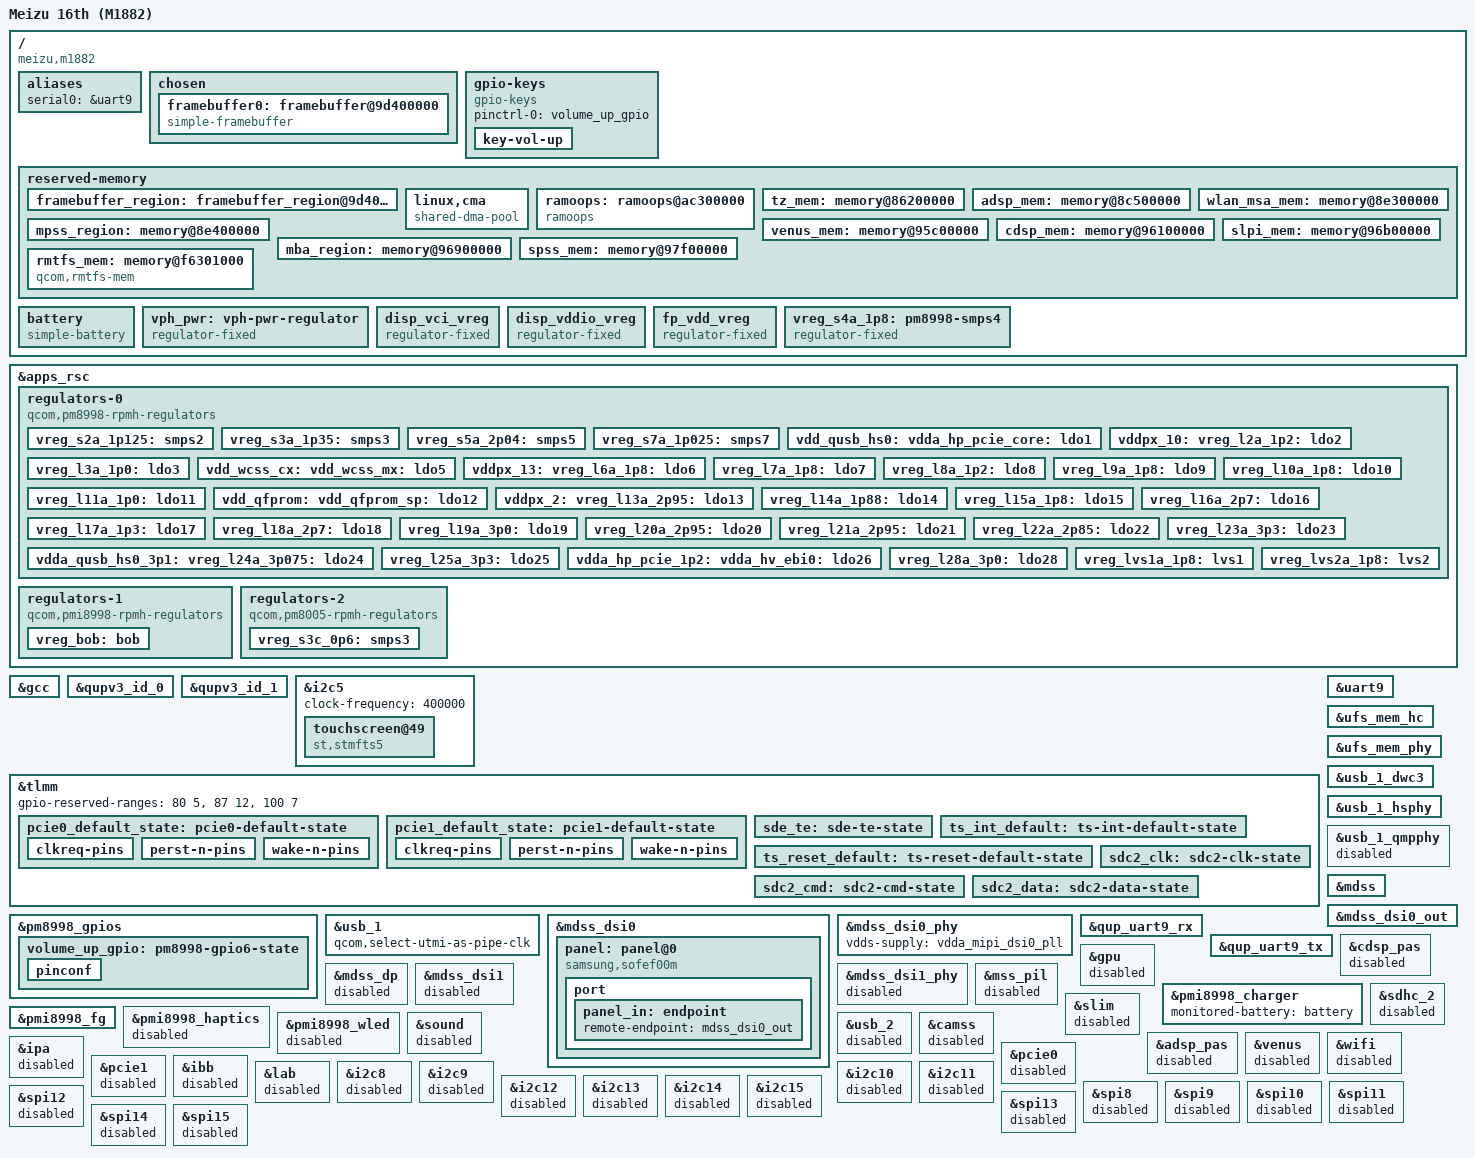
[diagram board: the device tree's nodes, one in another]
// SPDX-License-Identifier: GPL-2.0
/*
 * SDM845 Meizu 16th (M1882) device tree
 *
 * Copyright (c) 2026, The Linux Foundation. All rights reserved.
 */

/dts-v1/;

#include <dt-bindings/gpio/gpio.h>
#include <dt-bindings/input/linux-event-codes.h>
#include <dt-bindings/interrupt-controller/irq.h>
#include <dt-bindings/pinctrl/qcom,pmic-gpio.h>
#include <dt-bindings/regulator/qcom,rpmh-regulator.h>
#include <dt-bindings/arm/qcom,ids.h>
#include <dt-bindings/clock/qcom,gcc-sdm845.h>
#include "sdm845.dtsi"
#include "pm8998.dtsi"
#include "pmi8998.dtsi"

/delete-node/ &tz_mem;
/delete-node/ &adsp_mem;
/delete-node/ &wlan_msa_mem;
/delete-node/ &mpss_region;
/delete-node/ &venus_mem;
/delete-node/ &cdsp_mem;
/delete-node/ &mba_region;
/delete-node/ &slpi_mem;
/delete-node/ &spss_mem;
/delete-node/ &rmtfs_mem;

/ {
	model = "Meizu 16th (M1882)";
	compatible = "meizu,m1882", "qcom,sdm845";
	chassis-type = "handset";

	qcom,msm-id = <0x141 0x20001>;
	qcom,board-id = <0x08 0x00>;

	aliases {
		serial0 = &uart9;
	};

	chosen {
		#address-cells = <2>;
		#size-cells = <2>;
		ranges;

		stdout-path = "serial0:115200n8";

		bootargs = "console=tty0 earlycon keep_bootcon ignore_loglevel no_console_suspend";

		framebuffer0: framebuffer@9d400000 {
			compatible = "simple-framebuffer";
			memory-region = <&framebuffer_region>;

			format = "a8r8g8b8";
			width = <1080>;
			height = <2160>;
			stride = <(1080 * 4)>;
		};
	};

	gpio-keys {
		compatible = "gpio-keys";

		pinctrl-names = "default";
		pinctrl-0 = <&volume_up_gpio>;

		key-vol-up {
			label = "Volume up";
			linux,code = <KEY_VOLUMEUP>;
			gpios = <&pm8998_gpios 6 GPIO_ACTIVE_LOW>;
		};
	};

	reserved-memory {
		#address-cells = <2>;
		#size-cells = <2>;
		ranges;

		framebuffer_region: framebuffer_region@9d400000 {
			reg = <0x0 0x9d400000 0x0 0x02400000>;
			no-map;
		};

		linux,cma {
			compatible = "shared-dma-pool";
			alloc-ranges = <0 0x00000000 0 0xffffffff>;
			reusable;
			alignment = <0 0x400000>;
			size = <0 0x2c00000>;
			linux,cma-default;
		};

		ramoops: ramoops@ac300000 {
			compatible = "ramoops";
			reg = <0 0xac300000 0 0x400000>;
			record-size = <0x40000>;
			console-size = <0x40000>;
			ftrace-size = <0x40000>;
			pmsg-size = <0x200000>;
		};

		tz_mem: memory@86200000 {
			reg = <0 0x86200000 0 0x4900000>;
			no-map;
		};

		adsp_mem: memory@8c500000 {
			reg = <0 0x8c500000 0 0x1e00000>;
			no-map;
		};

		wlan_msa_mem: memory@8e300000 {
			reg = <0 0x8e300000 0 0x100000>;
			no-map;
		};

		mpss_region: memory@8e400000 {
			reg = <0 0x8e400000 0 0x7800000>;
			no-map;
		};

		venus_mem: memory@95c00000 {
			reg = <0 0x95c00000 0 0x500000>;
			no-map;
		};

		cdsp_mem: memory@96100000 {
			reg = <0 0x96100000 0 0x800000>;
			no-map;
		};

		mba_region: memory@96900000 {
			reg = <0 0x96900000 0 0x200000>;
			no-map;
		};

		slpi_mem: memory@96b00000 {
			reg = <0 0x96b00000 0 0x1400000>;
			no-map;
		};

		spss_mem: memory@97f00000 {
			reg = <0 0x97f00000 0 0x100000>;
			no-map;
		};

		rmtfs_mem: memory@f6301000 {
			compatible = "qcom,rmtfs-mem";
			reg = <0 0xf6301000 0 0x200000>;
			no-map;

			qcom,client-id = <1>;
			qcom,vmid = <QCOM_SCM_VMID_MSS_MSA>;
		};
	};

		battery: battery {
		compatible = "simple-battery";

		charge-full-design-microamp-hours = <3010000>;
		voltage-min-design-microvolt = <3300000>;
		voltage-max-design-microvolt = <4400000>;
		constant-charge-current-max-microamp = <2950000>;
	};

	vph_pwr: vph-pwr-regulator {
		compatible = "regulator-fixed";
		regulator-name = "vph_pwr";
		regulator-min-microvolt = <3700000>;
		regulator-max-microvolt = <3700000>;
	};

	disp_vci_vreg: disp_vci_vreg {
		compatible = "regulator-fixed";
		regulator-name = "disp_vci_vreg";
		start-delay-us = <4000>;
		regulator-always-on;
		regulator-boot-on;
		enable-active-high;
		gpio = <&tlmm 99 0>;
	};

	disp_vddio_vreg: disp_vddio_vreg {
		compatible = "regulator-fixed";
		regulator-name = "disp_vddio_vreg";
		startup-delay-us = <4000>;
		regulator-always-on;
		regulator-boot-on;
		enable-active-high;
		gpio = <&tlmm 79 0>;
	};

	fp_vdd_vreg: fp_vdd_vreg {
		compatible = "regulator-fixed";
		regulator-name = "fp_vdd_vreg";
		startup-delay-us = <4000>;
		regulator-always-on;
		enable-active-high;
		gpio = <&tlmm 50 0>;
	};

	vreg_s4a_1p8: pm8998-smps4 {
		compatible = "regulator-fixed";
		regulator-name = "vreg_s4a_1p8";

		regulator-min-microvolt = <1800000>;
		regulator-max-microvolt = <1800000>;

		regulator-always-on;
		regulator-boot-on;

		vin-supply = <&vph_pwr>;
	};
};

&apps_rsc {
	regulators-0 {
		compatible = "qcom,pm8998-rpmh-regulators";
		qcom,pmic-id = "a";

		vdd-s1-supply = <&vph_pwr>;
		vdd-s2-supply = <&vph_pwr>;
		vdd-s3-supply = <&vph_pwr>;
		vdd-s4-supply = <&vph_pwr>;
		vdd-s5-supply = <&vph_pwr>;
		vdd-s6-supply = <&vph_pwr>;
		vdd-s7-supply = <&vph_pwr>;
		vdd-s8-supply = <&vph_pwr>;
		vdd-s9-supply = <&vph_pwr>;
		vdd-s10-supply = <&vph_pwr>;
		vdd-s11-supply = <&vph_pwr>;
		vdd-s12-supply = <&vph_pwr>;
		vdd-s13-supply = <&vph_pwr>;
		vdd-l1-l27-supply = <&vreg_s7a_1p025>;
		vdd-l2-l8-l17-supply = <&vreg_s3a_1p35>;
		vdd-l3-l11-supply = <&vreg_s7a_1p025>;
		vdd-l4-l5-supply = <&vreg_s7a_1p025>;
		vdd-l6-supply = <&vph_pwr>;
		vdd-l7-l12-l14-l15-supply = <&vreg_s5a_2p04>;
		vdd-l9-supply = <&vreg_bob>;
		vdd-l10-l23-l25-supply = <&vreg_bob>;
		vdd-l13-l19-l21-supply = <&vreg_bob>;
		vdd-l16-l28-supply = <&vreg_bob>;
		vdd-l18-l22-supply = <&vreg_bob>;
		vdd-l20-l24-supply = <&vreg_bob>;
		vdd-l26-supply = <&vreg_s3a_1p35>;
		vin-lvs-1-2-supply = <&vreg_s4a_1p8>;

		vreg_s2a_1p125: smps2 {
			regulator-min-microvolt = <1100000>;
			regulator-max-microvolt = <1100000>;
		};

		vreg_s3a_1p35: smps3 {
			regulator-min-microvolt = <1352000>;
			regulator-max-microvolt = <1352000>;
		};

		vreg_s5a_2p04: smps5 {
			regulator-min-microvolt = <1904000>;
			regulator-max-microvolt = <2040000>;
		};

		vreg_s7a_1p025: smps7 {
			regulator-min-microvolt = <900000>;
			regulator-max-microvolt = <1028000>;
		};

		vdd_qusb_hs0:
		vdda_hp_pcie_core:
		vdda_mipi_csi0_0p9:
		vdda_mipi_csi1_0p9:
		vdda_mipi_csi2_0p9:
		vdda_mipi_dsi0_pll:
		vdda_mipi_dsi1_pll:
		vdda_qlink_lv:
		vdda_qlink_lv_ck:
		vdda_qrefs_0p875:
		vdda_pcie_core:
		vdda_pll_cc_ebi01:
		vdda_pll_cc_ebi23:
		vdda_sp_sensor:
		vdda_ufs1_core:
		vdda_ufs2_core:
		vdda_usb1_ss_core:
		vdda_usb2_ss_core:
		vreg_l1a_0p875: ldo1 {
			regulator-min-microvolt = <880000>;
			regulator-max-microvolt = <880000>;
			regulator-initial-mode = <RPMH_REGULATOR_MODE_HPM>;
		};

		vddpx_10:
		vreg_l2a_1p2: ldo2 {
			regulator-min-microvolt = <1200000>;
			regulator-max-microvolt = <1200000>;
			regulator-initial-mode = <RPMH_REGULATOR_MODE_HPM>;
			regulator-always-on;
		};

		vreg_l3a_1p0: ldo3 {
			regulator-min-microvolt = <1000000>;
			regulator-max-microvolt = <1000000>;
			regulator-initial-mode = <RPMH_REGULATOR_MODE_HPM>;
		};

		vdd_wcss_cx:
		vdd_wcss_mx:
		vdda_wcss_pll:
		vreg_l5a_0p8: ldo5 {
			regulator-min-microvolt = <800000>;
			regulator-max-microvolt = <800000>;
			regulator-initial-mode = <RPMH_REGULATOR_MODE_HPM>;
		};

		vddpx_13:
		vreg_l6a_1p8: ldo6 {
			regulator-min-microvolt = <1856000>;
			regulator-max-microvolt = <1856000>;
			regulator-initial-mode = <RPMH_REGULATOR_MODE_HPM>;
		};

		vreg_l7a_1p8: ldo7 {
			regulator-min-microvolt = <1800000>;
			regulator-max-microvolt = <1800000>;
			regulator-initial-mode = <RPMH_REGULATOR_MODE_HPM>;
		};

		vreg_l8a_1p2: ldo8 {
			regulator-min-microvolt = <1200000>;
			regulator-max-microvolt = <1248000>;
			regulator-initial-mode = <RPMH_REGULATOR_MODE_HPM>;
		};

		vreg_l9a_1p8: ldo9 {
			regulator-min-microvolt = <1704000>;
			regulator-max-microvolt = <2928000>;
			regulator-initial-mode = <RPMH_REGULATOR_MODE_HPM>;
		};

		vreg_l10a_1p8: ldo10 {
			regulator-min-microvolt = <1704000>;
			regulator-max-microvolt = <2928000>;
			regulator-initial-mode = <RPMH_REGULATOR_MODE_HPM>;
		};

		vreg_l11a_1p0: ldo11 {
			regulator-min-microvolt = <1000000>;
			regulator-max-microvolt = <1048000>;
			regulator-initial-mode = <RPMH_REGULATOR_MODE_HPM>;
		};

		vdd_qfprom:
		vdd_qfprom_sp:
		vdda_apc1_cs_1p8:
		vdda_gfx_cs_1p8:
		vdda_qrefs_1p8:
		vdda_qusb_hs0_1p8:
		vddpx_11:
		vreg_l12a_1p8: ldo12 {
			regulator-min-microvolt = <1800000>;
			regulator-max-microvolt = <1800000>;
			regulator-initial-mode = <RPMH_REGULATOR_MODE_HPM>;
		};

		vddpx_2:
		vreg_l13a_2p95: ldo13 {
			regulator-min-microvolt = <1800000>;
			regulator-max-microvolt = <2960000>;
			regulator-initial-mode = <RPMH_REGULATOR_MODE_HPM>;
		};

		vreg_l14a_1p88: ldo14 {
			regulator-min-microvolt = <1800000>;
			regulator-max-microvolt = <1800000>;
			regulator-initial-mode = <RPMH_REGULATOR_MODE_HPM>;
		};

		vreg_l15a_1p8: ldo15 {
			regulator-min-microvolt = <1800000>;
			regulator-max-microvolt = <1800000>;
			regulator-initial-mode = <RPMH_REGULATOR_MODE_HPM>;
		};

		vreg_l16a_2p7: ldo16 {
			regulator-min-microvolt = <2704000>;
			regulator-max-microvolt = <2704000>;
			regulator-initial-mode = <RPMH_REGULATOR_MODE_HPM>;
		};

		vreg_l17a_1p3: ldo17 {
			regulator-min-microvolt = <1304000>;
			regulator-max-microvolt = <1304000>;
			regulator-initial-mode = <RPMH_REGULATOR_MODE_HPM>;
		};

		vreg_l18a_2p7: ldo18 {
			regulator-min-microvolt = <2704000>;
			regulator-max-microvolt = <2960000>;
			regulator-initial-mode = <RPMH_REGULATOR_MODE_HPM>;
		};

		vreg_l19a_3p0: ldo19 {
			regulator-min-microvolt = <2856000>;
			regulator-max-microvolt = <3104000>;
			regulator-initial-mode = <RPMH_REGULATOR_MODE_HPM>;
		};

		vreg_l20a_2p95: ldo20 {
			regulator-min-microvolt = <2704000>;
			regulator-max-microvolt = <2960000>;
			regulator-initial-mode = <RPMH_REGULATOR_MODE_HPM>;
		};

		vreg_l21a_2p95: ldo21 {
			regulator-min-microvolt = <2704000>;
			regulator-max-microvolt = <2960000>;
			regulator-initial-mode = <RPMH_REGULATOR_MODE_HPM>;
		};

		vreg_l22a_2p85: ldo22 {
			regulator-min-microvolt = <2864000>;
			regulator-max-microvolt = <3312000>;
			regulator-initial-mode = <RPMH_REGULATOR_MODE_HPM>;
		};

		vreg_l23a_3p3: ldo23 {
			regulator-min-microvolt = <3000000>;
			regulator-max-microvolt = <3312000>;
			regulator-initial-mode = <RPMH_REGULATOR_MODE_HPM>;
		};

		vdda_qusb_hs0_3p1:
		vreg_l24a_3p075: ldo24 {
			regulator-min-microvolt = <3088000>;
			regulator-max-microvolt = <3088000>;
			regulator-initial-mode = <RPMH_REGULATOR_MODE_HPM>;
		};

		vreg_l25a_3p3: ldo25 {
			regulator-min-microvolt = <3300000>;
			regulator-max-microvolt = <3312000>;
			regulator-initial-mode = <RPMH_REGULATOR_MODE_HPM>;
		};

		vdda_hp_pcie_1p2:
		vdda_hv_ebi0:
		vdda_hv_ebi1:
		vdda_hv_ebi2:
		vdda_hv_ebi3:
		vdda_mipi_csi_1p25:
		vdda_mipi_dsi0_1p2:
		vdda_mipi_dsi1_1p2:
		vdda_pcie_1p2:
		vdda_ufs1_1p2:
		vdda_ufs2_1p2:
		vdda_usb1_ss_1p2:
		vdda_usb2_ss_1p2:
		vreg_l26a_1p2: ldo26 {
			regulator-min-microvolt = <1200000>;
			regulator-max-microvolt = <1200000>;
			regulator-initial-mode = <RPMH_REGULATOR_MODE_HPM>;
		};

		vreg_l28a_3p0: ldo28 {
			regulator-min-microvolt = <2856000>;
			regulator-max-microvolt = <3008000>;
			regulator-initial-mode = <RPMH_REGULATOR_MODE_HPM>;
		};

		vreg_lvs1a_1p8: lvs1 {
			regulator-min-microvolt = <1800000>;
			regulator-max-microvolt = <1800000>;
		};

		vreg_lvs2a_1p8: lvs2 {
			regulator-min-microvolt = <1800000>;
			regulator-max-microvolt = <1800000>;
		};
	};

	regulators-1 {
		compatible = "qcom,pmi8998-rpmh-regulators";
		qcom,pmic-id = "b";

		vdd-bob-supply = <&vph_pwr>;

		vreg_bob: bob {
			regulator-min-microvolt = <3312000>;
			regulator-max-microvolt = <3600000>;
			regulator-initial-mode = <RPMH_REGULATOR_MODE_AUTO>;
			regulator-allow-bypass;
		};
	};

	regulators-2 {
		compatible = "qcom,pm8005-rpmh-regulators";
		qcom,pmic-id = "c";

		vdd-s1-supply = <&vph_pwr>;
		vdd-s2-supply = <&vph_pwr>;
		vdd-s3-supply = <&vph_pwr>;
		vdd-s4-supply = <&vph_pwr>;

		vreg_s3c_0p6: smps3 {
			regulator-min-microvolt = <600000>;
			regulator-max-microvolt = <600000>;
		};
	};
};

&gcc {
	protected-clocks = <GCC_QSPI_CORE_CLK>,
			   <GCC_QSPI_CORE_CLK_SRC>,
			   <GCC_QSPI_CNOC_PERIPH_AHB_CLK>,
			   <GCC_LPASS_Q6_AXI_CLK>,
			   <GCC_LPASS_SWAY_CLK>,
			   <GCC_CPUSS_AHB_CLK>,
			   <GCC_CPUSS_AHB_CLK_SRC>,
			   <GCC_CPUSS_RBCPR_CLK>,
			   <GCC_CPUSS_RBCPR_CLK_SRC>,
			   <GCC_SYS_NOC_CPUSS_AHB_CLK>,
			   <GCC_CPUSS_DVM_BUS_CLK>,
			   <GCC_CPUSS_GNOC_CLK>;
};

&qupv3_id_0 {
	status = "okay";
};

&qupv3_id_1 {
	status = "okay";
};

&i2c5 {
	clock-frequency = <400000>;

	status = "okay";

	touchscreen@49 {
		compatible = "st,stmfts5";
		reg = <0x49>;

		interrupts-extended = <&tlmm 125 IRQ_TYPE_LEVEL_LOW>;

		reset-gpios = <&tlmm 126 GPIO_ACTIVE_LOW>;

		pinctrl-names = "default";
		pinctrl-0 = <&ts_int_default &ts_reset_default>;

		avdd-supply = <&vreg_l28a_3p0>;
		vdd-supply = <&vreg_l14a_1p88>;

		touchscreen-size-x = <1080>;
		touchscreen-size-y = <2160>;
	};
};

&tlmm {
	pcie0_default_state: pcie0-default-state {
		clkreq-pins {
			pins = "gpio36";
			function = "pci_e0";
			bias-pull-up;
		};

		perst-n-pins {
			pins = "gpio35";
			function = "gpio";
			drive-strength = <2>;
			bias-pull-down;
		};

		wake-n-pins {
			pins = "gpio37";
			function = "gpio";
			drive-strength = <2>;
			bias-pull-up;
		};
	};

	pcie1_default_state: pcie1-default-state {
		clkreq-pins {
			pins = "gpio103";
			function = "pci_e1";
			bias-pull-up;
		};

		perst-n-pins {
			pins = "gpio102";
			function = "gpio";
			drive-strength = <16>;
			bias-pull-down;
		};

		wake-n-pins {
			pins = "gpio104";
			function = "gpio";
			drive-strength = <2>;
			bias-pull-up;
		};
	};
};

&pm8998_gpios {
	volume_up_gpio: pm8998-gpio6-state {
		pinconf {
			pins = "gpio6";
			function = "normal";
			input-enable;
			bias-pull-up;
			qcom,drive-strength = <PMIC_GPIO_STRENGTH_NO>;
		};
	};
};

&uart9 {
	status = "okay";
};

&ufs_mem_hc {
	status = "okay";

	reset-gpios = <&tlmm 150 GPIO_ACTIVE_LOW>;

	vcc-supply = <&vreg_l20a_2p95>;
	vcc-max-microamp = <600000>;
};

&ufs_mem_phy {
	status = "okay";

	vdda-phy-supply = <&vdda_ufs1_core>;
	vdda-pll-supply = <&vdda_ufs1_1p2>;
};

&usb_1 {
	qcom,select-utmi-as-pipe-clk;

	status = "okay";
};

&usb_1_dwc3 {
	dr_mode = "peripheral";

	maximum-speed = "high-speed";

	phys = <&usb_1_hsphy>;
	phy-names = "usb2-phy";
};

&usb_1_hsphy {
	status = "okay";

	vdd-supply = <&vdda_usb1_ss_core>;
	vdda-pll-supply = <&vdda_qusb_hs0_1p8>;
	vdda-phy-dpdm-supply = <&vdda_qusb_hs0_3p1>;

	post-init-providers = <&vreg_l1a_0p875
			       &vreg_l12a_1p8
			       &vreg_l24a_3p075>;

	qcom,imp-res-offset-value = <8>;
	qcom,hstx-trim-value = <QUSB2_V2_HSTX_TRIM_21_6_MA>;
	qcom,preemphasis-level = <QUSB2_V2_PREEMPHASIS_5_PERCENT>;
	qcom,preemphasis-width = <QUSB2_V2_PREEMPHASIS_WIDTH_HALF_BIT>;
};

&usb_1_qmpphy {
	status = "disabled";
};

&mdss {
	status = "okay";
};

&mdss_dsi0 {
	status = "okay";
	vdda-supply = <&vdda_mipi_dsi0_1p2>;

	pinctrl-names = "default", "sleep";
	pinctrl-0 = <&sde_te>;
	pinctrl-1 = <&sde_te>;

	panel: panel@0 {
		compatible = "samsung,sofef00m";
		reg = <0>;

		vddio-supply = <&disp_vddio_vreg>;
		vdd-supply = <&disp_vci_vreg>;

		reset-gpios = <&pm8998_gpios 8 GPIO_ACTIVE_LOW>;

		port {
			panel_in: endpoint {
				remote-endpoint = <&mdss_dsi0_out>;
			};
		};
	};
};

&mdss_dsi0_out {
	remote-endpoint = <&panel_in>;
	data-lanes = <0 1 2 3>;
};

&mdss_dsi0_phy {
	status = "okay";
	vdds-supply = <&vdda_mipi_dsi0_pll>;
};

&qup_uart9_rx {
	drive-strength = <2>;
	bias-pull-up;
};

&qup_uart9_tx {
	drive-strength = <2>;
	bias-disable;
};

&tlmm {
	gpio-reserved-ranges = <80 5>, <87 12>, <100 7>;

	sde_te: sde-te-state {
		pins = "gpio10";
		function = "mdp_vsync";
		drive-strength = <2>;
		bias-pull-down;
	};

	ts_int_default: ts-int-default-state {
		pins = "gpio125";
		function = "gpio";
		drive-strength = <2>;
		bias-pull-up;
	};

	ts_reset_default: ts-reset-default-state {
		pins = "gpio126";
		function = "gpio";
		drive-strength = <2>;
		bias-disable;
	};

	sdc2_clk: sdc2-clk-state {
		pins = "sdc2_clk";
		bias-disable;
		drive-strength = <16>;
	};

	sdc2_cmd: sdc2-cmd-state {
		pins = "sdc2_cmd";
		bias-pull-up;
		drive-strength = <16>;
	};

	sdc2_data: sdc2-data-state {
		pins = "sdc2_data";
		bias-pull-up;
		drive-strength = <16>;
	};
};

&cdsp_pas { status = "disabled"; };
&gpu { status = "disabled"; };
&mdss_dp { status = "disabled"; };
&mdss_dsi1 { status = "disabled"; };
&mdss_dsi1_phy { status = "disabled"; };
&mss_pil { status = "disabled"; };
&pmi8998_charger {
	monitored-battery = <&battery>;

	status = "okay";
};

&pmi8998_fg {
	monitored-battery = <&battery>;
	power-supplies = <&pmi8998_charger>;

	status = "okay";
};

&pmi8998_haptics { status = "disabled"; };
&pmi8998_wled { status = "disabled"; };
&sdhc_2 { status = "disabled"; };
&slim { status = "disabled"; };
&sound { status = "disabled"; };
&usb_2 { status = "disabled"; };

&camss { status = "disabled"; };
&adsp_pas { status = "disabled"; };
&venus { status = "disabled"; };
&wifi { status = "disabled"; };
&ipa { status = "disabled"; };
&pcie0 { status = "disabled"; };
&pcie1 { status = "disabled"; };
&ibb { status = "disabled"; };
&lab { status = "disabled"; };

&i2c8 { status = "disabled"; };
&i2c9 { status = "disabled"; };
&i2c10 { status = "disabled"; };
&i2c11 { status = "disabled"; };
&i2c12 { status = "disabled"; };
&i2c13 { status = "disabled"; };
&i2c14 { status = "disabled"; };
&i2c15 { status = "disabled"; };
&spi8 { status = "disabled"; };
&spi9 { status = "disabled"; };
&spi10 { status = "disabled"; };
&spi11 { status = "disabled"; };
&spi12 { status = "disabled"; };
&spi13 { status = "disabled"; };
&spi14 { status = "disabled"; };
&spi15 { status = "disabled"; };
